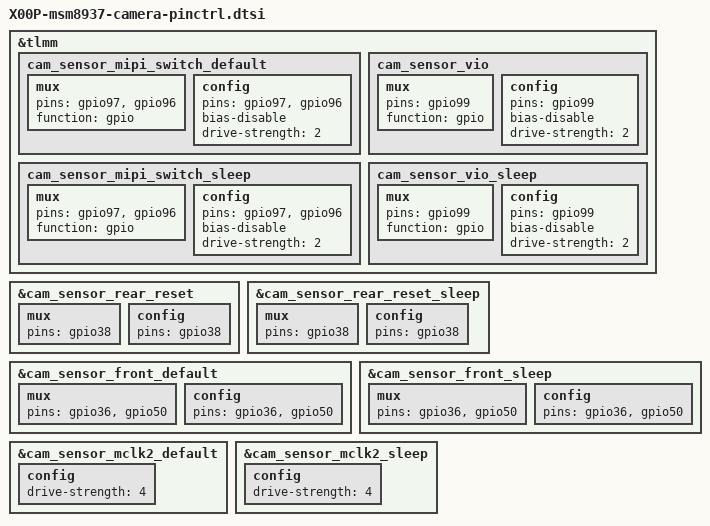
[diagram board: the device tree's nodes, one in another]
/*
 * Copyright (c) 2017, The Linux Foundation. All rights reserved.
 *
 * This program is free software; you can redistribute it and/or modify
 * it under the terms of the GNU General Public License version 2 and
 * only version 2 as published by the Free Software Foundation.
 *
 * This program is distributed in the hope that it will be useful,
 * but WITHOUT ANY WARRANTY; without even the implied warranty of
 * MERCHANTABILITY or FITNESS FOR A PARTICULAR PURPOSE.  See the
 * GNU General Public License for more details.
 */

&tlmm {
	cam_sensor_mipi_switch_default: cam_sensor_mipi_switch_default {
		/* RESET, STANDBY */
		mux {
			pins = "gpio97", "gpio96";
			function = "gpio";
		};

		config {
			pins = "gpio97","gpio96";
			bias-disable; /* No PULL */
			drive-strength = <2>; /* 2 MA */
		};
	};

	cam_sensor_mipi_switch_sleep: cam_sensor_mipi_switch_sleep {
		/* RESET, STANDBY */
		mux {
			pins = "gpio97","gpio96";
			function = "gpio";
		};

		config {
			pins = "gpio97","gpio96";
			bias-disable; /* No PULL */
			drive-strength = <2>; /* 2 MA */
		};
	};

	cam_sensor_vio: cam_sensor_vio {
		/* VIO */
		mux {
			pins = "gpio99";
			function = "gpio";
		};

		config {
			pins = "gpio99";
			bias-disable; /* No PULL */
			drive-strength = <2>; /* 2 MA */
		};
	};

	cam_sensor_vio_sleep: cam_sensor_vio_sleep {
		/* VIO */
		mux {
			pins = "gpio99";
			function = "gpio";
		};

		config {
			pins = "gpio99";
			bias-disable; /* No PULL */
			drive-strength = <2>; /* 2 MA */
		};
	};
};

&cam_sensor_rear_reset {
	mux {
		pins = "gpio38";
	};

	config {
		pins = "gpio38";
	};
};

&cam_sensor_rear_reset_sleep {
	mux {
		pins = "gpio38";
	};

	config {
		pins = "gpio38";
	};
};

&cam_sensor_front_default {
	mux {
		pins = "gpio36","gpio50";
	};

	config {
		pins = "gpio36","gpio50";
	};
};

&cam_sensor_front_sleep {
	mux {
		pins = "gpio36","gpio50";
	};

	config {
		pins = "gpio36","gpio50";
	};
};

&cam_sensor_mclk2_default {
	config {
		drive-strength = <4>;
	};
};

&cam_sensor_mclk2_sleep {
	config {
		drive-strength = <4>;
	};
};
